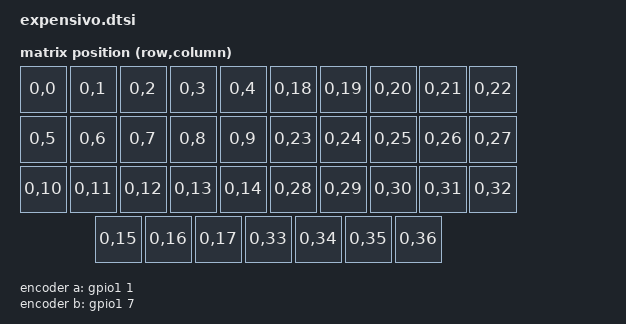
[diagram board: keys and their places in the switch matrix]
// Generated by scripts/gen_zmk.py -- edit the generator, not this file.
#include <dt-bindings/zmk/matrix_transform.h>
#include "expensivo-layout.dtsi"

// P0.09 / P0.10 are used as key inputs
&uicr {
    nfct-pins-as-gpios;
};

&expensivo_layout {
    transform = <&default_transform>;
};

/ {
    chosen {
        zmk,kscan = &kscan0;
        zmk,physical-layout = &expensivo_layout;
    };

    default_transform: keymap_transform_0 {
        compatible = "zmk,matrix-transform";
        columns = <37>;
        rows = <1>;
        // last entry is the (optional) encoder push on the right half
        map = <
            RC(0,0) RC(0,1) RC(0,2) RC(0,3) RC(0,4)    RC(0,18) RC(0,19) RC(0,20) RC(0,21) RC(0,22)
            RC(0,5) RC(0,6) RC(0,7) RC(0,8) RC(0,9)    RC(0,23) RC(0,24) RC(0,25) RC(0,26) RC(0,27)
            RC(0,10) RC(0,11) RC(0,12) RC(0,13) RC(0,14)    RC(0,28) RC(0,29) RC(0,30) RC(0,31) RC(0,32)
                            RC(0,15) RC(0,16) RC(0,17)    RC(0,33) RC(0,34) RC(0,35)   RC(0,36)
        >;
    };

    kscan0: kscan {
        compatible = "zmk,kscan-gpio-direct";
        wakeup-source;
    };

    encoder: encoder {
        compatible = "alps,ec11";
        a-gpios = <&gpio1 1 (GPIO_ACTIVE_HIGH | GPIO_PULL_UP)>;
        b-gpios = <&gpio1 7 (GPIO_ACTIVE_HIGH | GPIO_PULL_UP)>;
        steps = <80>;
        status = "disabled";
    };

    sensors: sensors {
        compatible = "zmk,keymap-sensors";
        sensors = <&encoder>;
        triggers-per-rotation = <20>;
    };
};
